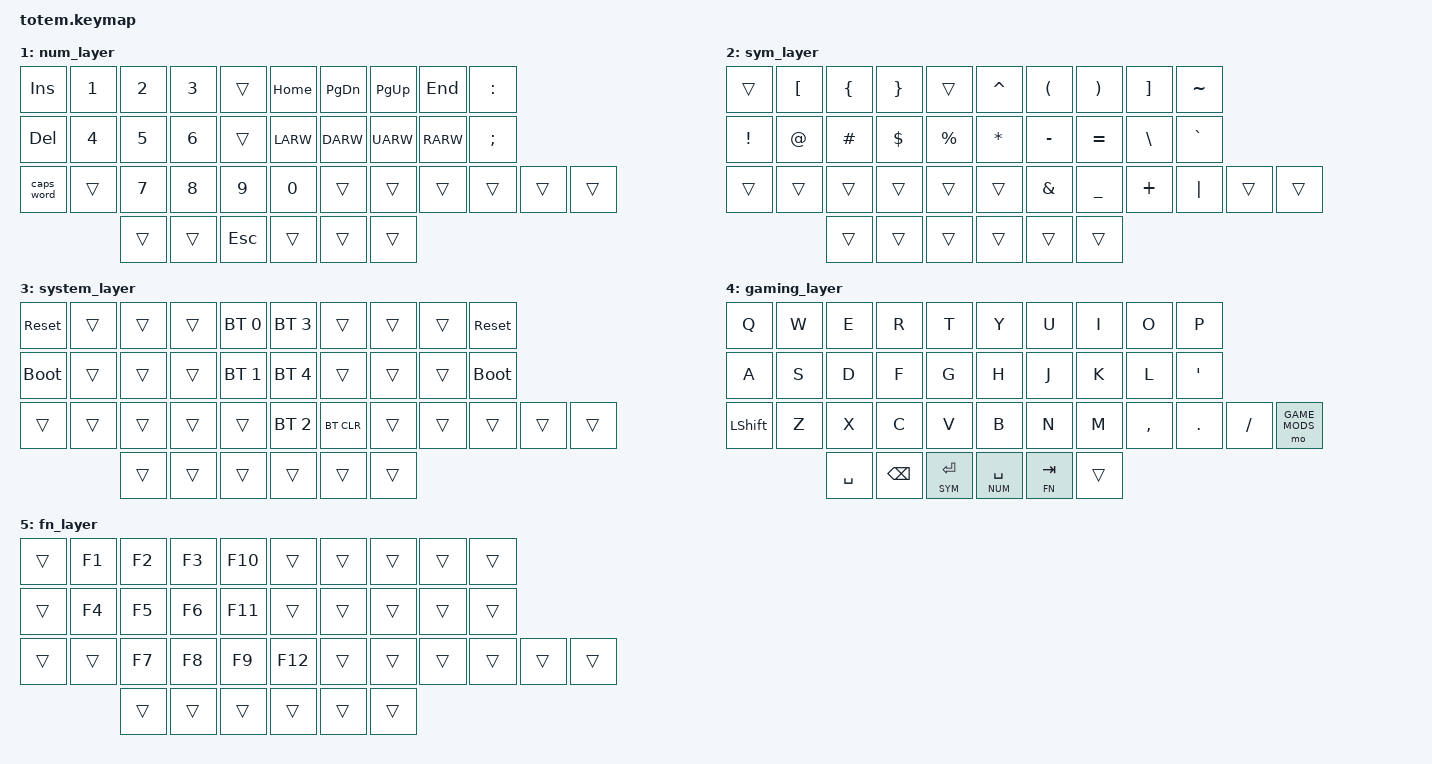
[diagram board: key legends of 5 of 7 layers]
//
//                                                        ▀▀▀▀▀     ▀▀▀▀▀          ▀▀█▀▀
//                                                        ▄▀▀▀▄  ▄  ▄▀▀▀▄  ▄  ▄▀▀▀▄  █  ▄▀▀▀▄
//                                                        █   █  █  █   █  █  █   █  █  █   █
//                                                         ▀▀▀   █   ▀▀▀   █   ▀▀▀   ▀   ▀▀▀
//                                                               █      ▄▄▄█▄▄▄    █   █  
//                                                               ▀      █  █  █     █▄█
//                                                             ▀▀▀▀▀    █  █  █      ▀
//                                                                      ▀  ▀  ▀
//
// Migrated from Crab Broom (34-key) to Totem (38-key) layout
//
// ▄▄▄▄▄▄▄▄▄▄▄▄▄▄▄▄▄▄▄▄▄▄▄▄▄▄▄▄▄▄▄▄▄▄▄▄▄▄▄▄▄▄▄▄▄▄▄▄▄▄▄▄▄▄▄▄▄▄▄▄▄▄▄▄▄▄▄▄▄▄▄▄▄▄▄▄▄▄▄▄▄▄▄▄▄▄▄▄▄▄▄▄▄▄▄▄▄▄▄▄▄▄▄▄▄▄▄▄▄▄▄▄▄▄▄▄▄▄▄▄▄▄▄▄▄▄▄▄▄▄▄▄▄▄▄▄▄▄▄▄▄▄▄▄▄▄▄▄▄

// Key position layout (Totem 38-key):
//             ┏━━━━━━━━━━━┳━━━━━━━━━━━┳━━━━━━━━━━━┳━━━━━━━━━━━┳━━━━━━━━━━━┓   ┏━━━━━━━━━━━┳━━━━━━━━━━━┳━━━━━━━━━━━┳━━━━━━━━━━━┳━━━━━━━━━━━┓
//             ┃     0     ┃     1     ┃     2     ┃     3     ┃     4     ┃   ┃     5     ┃     6     ┃     7     ┃     8     ┃     9     ┃
//             ┣━━━━━━━━━━━╋━━━━━━━━━━━╋━━━━━━━━━━━╋━━━━━━━━━━━╋━━━━━━━━━━━┫   ┣━━━━━━━━━━━╋━━━━━━━━━━━╋━━━━━━━━━━━╋━━━━━━━━━━━╋━━━━━━━━━━━┫
//             ┃    10     ┃    11     ┃    12     ┃    13     ┃    14     ┃   ┃    15     ┃    16     ┃    17     ┃    18     ┃    19     ┃
// ┏━━━━━━━━━━━╋━━━━━━━━━━━╋━━━━━━━━━━━╋━━━━━━━━━━━╋━━━━━━━━━━━╋━━━━━━━━━━━┫   ┣━━━━━━━━━━━╋━━━━━━━━━━━╋━━━━━━━━━━━╋━━━━━━━━━━━╋━━━━━━━━━━━╋━━━━━━━━━━━┓
// ┃    20     ┃    21     ┃    22     ┃    23     ┃    24     ┃    25     ┃   ┃    26     ┃    27     ┃    28     ┃    29     ┃    30     ┃    31     ┃
// ┗━━━━━━━━━━━┻━━━━━━━━━━━┻━━━━━━━━━━━╋━━━━━━━━━━━╋━━━━━━━━━━━╋━━━━━━━━━━━┫   ┣━━━━━━━━━━━╋━━━━━━━━━━━╋━━━━━━━━━━━╋━━━━━━━━━━━┻━━━━━━━━━━━┻━━━━━━━━━━━┛
//                                     ┃    32     ┃    33     ┃    34     ┃   ┃    35     ┃    36     ┃    37     ┃
//                                     ┗━━━━━━━━━━━┻━━━━━━━━━━━┻━━━━━━━━━━━┛   ┗━━━━━━━━━━━┻━━━━━━━━━━━┻━━━━━━━━━━━┛
       

#include <behaviors.dtsi>
#include <dt-bindings/zmk/keys.h>
#include <dt-bindings/zmk/bt.h>
#include <dt-bindings/zmk/outputs.h>

// Layer definitions
#define BASE      0  // Main typing layer with QWERTY + home row mods
#define NUM       1  // Numbers, navigation, and function keys  
#define SYM       2  // Symbols and special characters
#define SYS       3  // System controls (bluetooth, reset, etc.)
#define GAME      4  // Gaming layer without home row mods
#define FN        5  // Function keys layer (F1-F12)
#define GAME_MODS 6  // Gaming modifiers layer (home row mods for gaming)

// Home row mods macros
// Left hand: Shift/Alt/Ctrl/Gui on A/S/D/F
// Right hand: Gui/Ctrl/Alt/Shift on J/K/L/'
#define HRML(k1,k2,k3,k4) &ht LSHFT k1  &ht LALT k2  &ht LCTRL k3  &ht LGUI k4
#define HRMR(k1,k2,k3,k4) &ht RGUI k1  &ht RCTRL k2  &ht RALT k3  &ht RSHFT k4

&mt {
  quick-tap-ms = <150>;
  global-quick-tap;
  flavor = "tap-preferred";
  tapping-term-ms = <220>;
  require-prior-idle-ms = <100>;
};

/ {
    behaviors {
        ht: hold_tap {
            compatible = "zmk,behavior-hold-tap";
            #binding-cells = <2>;
            flavor = "tap-preferred";
            tapping-term-ms = <220>;
            quick-tap-ms = <150>;
            require-prior-idle-ms = <100>;
            bindings = <&kp>, <&kp>;
        };

        // Enables holding the first mod-tap key
        // by performing a tap-release-hold sequence.
        qt: quick_tap {
            compatible = "zmk,behavior-hold-tap";
            #binding-cells = <2>;
            flavor = "hold-preferred";
            tapping-term-ms = <200>;
            quick-tap-ms = <200>;
            bindings = <&kp>, <&kp>;
        };
    };

    macros {
        // sometimes my device thinks a modifier is being held down
        // pressing all modifiers fixes it.
        unstick: unstick {
            compatible = "zmk,behavior-macro";
            #binding-cells = <0>;
            bindings = <&kp LSHIFT &kp RSHIFT &kp LCTRL &kp RCTRL &kp LALT &kp RALT &kp LGUI &kp RGUI>;
        };
    };

     combos {
            compatible = "zmk,combos";
            // Toggle gaming layer by pressing ALL 6 thumb keys simultaneously
            // This prevents accidental gaming mode activation during normal typing
            combo_gaming {
                timeout-ms = <200>;
                key-positions = <32 33 34 35 36 37>;  // All thumb keys: LALT BSPC SYM+ENTER NUM+SPACE FN+TAB RALT
                bindings = <&tog GAME>;
            };
    };

    conditional_layers {
        compatible = "zmk,conditional-layers";
        // Activate SYS layer when both NUM and SYM layers are held
        // Provides access to system functions like bluetooth and reset
        tri_layer {
            if-layers = <NUM SYM>;
            then-layer = <SYS>;
        };
    };

        keymap {
                compatible = "zmk,keymap";
// ▄▄▄▄▄▄▄▄▄▄▄▄▄▄▄▄▄▄▄▄▄▄▄▄▄▄▄▄▄▄▄▄▄▄▄▄▄▄▄▄▄▄▄▄▄▄▄▄▄▄▄▄▄▄▄▄▄▄▄▄▄▄▄▄▄▄▄▄▄▄▄▄▄▄▄▄▄▄▄▄▄▄▄▄▄▄▄▄▄▄▄▄▄▄▄▄▄▄▄▄▄▄▄▄▄▄▄▄▄▄▄▄▄▄▄▄▄▄▄▄▄▄▄▄▄▄▄▄▄▄▄▄▄▄▄▄▄▄▄▄▄▄▄▄▄▄▄▄▄

                base_layer {
// ┏━━━━━━━━━━━━━━━━━━━━━━━━━━━━━━━━━━━━━━━┓
// Base Layer
// ┗━━━━━━━━━━━━━━━━━━━━━━━━━━━━━━━━━━━━━━━┛
// Main QWERTY layer with home row mods for efficient typing
// Home row mods: A/S/D/F = Shift/Alt/Ctrl/Gui (left hand)
//                J/K/L/' = Gui/Ctrl/Alt/Shift (right hand)
//             ┏━━━━━━━━━━━┳━━━━━━━━━━━┳━━━━━━━━━━━┳━━━━━━━━━━━┳━━━━━━━━━━━┓   ┏━━━━━━━━━━━┳━━━━━━━━━━━┳━━━━━━━━━━━┳━━━━━━━━━━━┳━━━━━━━━━━━┓
//             ┃     Q     ┃     W     ┃     E     ┃     R     ┃     T     ┃   ┃     Y     ┃     U     ┃     I     ┃     O     ┃     P     ┃
//             ┣━━━━━━━━━━━╋━━━━━━━━━━━╋━━━━━━━━━━━╋━━━━━━━━━━━╋━━━━━━━━━━━┫   ┣━━━━━━━━━━━╋━━━━━━━━━━━╋━━━━━━━━━━━╋━━━━━━━━━━━╋━━━━━━━━━━━┫
//             ┃  A/SHFT   ┃   S/ALT   ┃  D/CTRL   ┃   F/GUI   ┃     G     ┃   ┃     H     ┃   J/GUI   ┃  K/CTRL   ┃   L/ALT   ┃ '/SHFT    ┃
// ┏━━━━━━━━━━━╋━━━━━━━━━━━╋━━━━━━━━━━━╋━━━━━━━━━━━╋━━━━━━━━━━━╋━━━━━━━━━━━┫   ┣━━━━━━━━━━━╋━━━━━━━━━━━╋━━━━━━━━━━━╋━━━━━━━━━━━╋━━━━━━━━━━━╋━━━━━━━━━━━┓
// ┃   SHIFT   ┃     Z     ┃     X     ┃     C     ┃     V     ┃     B     ┃   ┃     N     ┃     M     ┃     ,     ┃     .     ┃     /     ┃   SHIFT   ┃
// ┗━━━━━━━━━━━┻━━━━━━━━━━━┻━━━━━━━━━━━╋━━━━━━━━━━━╋━━━━━━━━━━━╋━━━━━━━━━━━┫   ┣━━━━━━━━━━━╋━━━━━━━━━━━╋━━━━━━━━━━━╋━━━━━━━━━━━┻━━━━━━━━━━━┻━━━━━━━━━━━┛
//                                     ┃   LALT    ┃   BSPC    ┃SYM+ENTER  ┃   ┃NUM+SPACE  ┃  FN+TAB   ┃   RALT    ┃
//                                     ┗━━━━━━━━━━━┻━━━━━━━━━━━┻━━━━━━━━━━━┛   ┗━━━━━━━━━━━┻━━━━━━━━━━━┻━━━━━━━━━━━┛
 bindings = <
// ╷           ╷           ╷           ╷           ╷           ╷           ╷   ╷           ╷           ╷           ╷           ╷           ╷           ╷
//   0           1           2           3           4               5           6           7           8           9
    &kp Q       &kp W       &kp E       &kp R       &kp T           &kp Y       &kp U       &kp I       &kp O       &kp P
//   10          11          12          13          14              15          16          17          18          19
  HRML(A,         S,          D,          F)        &kp G           &kp H     HRMR(J,         K,          L,        SQT) 
//   20          21          22          23          24          25              26          27          28          29          30          31
&kp LSHFT     &kp Z       &kp X       &kp C       &kp V       &kp B           &kp N       &kp M       &kp COMMA   &kp DOT     &kp FSLH    &kp RSHFT
//                          32          33          34              35          36          37
                            &kp LALT    &kp BSPC    &lt SYM ENTER   &lt NUM SPACE  &lt FN TAB   &kp RALT
                        >;
                };

// ▄▄▄▄▄▄▄▄▄▄▄▄▄▄▄▄▄▄▄▄▄▄▄▄▄▄▄▄▄▄▄▄▄▄▄▄▄▄▄▄▄▄▄▄▄▄▄▄▄▄▄▄▄▄▄▄▄▄▄▄▄▄▄▄▄▄▄▄▄▄▄▄▄▄▄▄▄▄▄▄▄▄▄▄▄▄▄▄▄▄▄▄▄▄▄▄▄▄▄▄▄▄▄▄▄▄▄▄▄▄▄▄▄▄▄▄▄▄▄▄▄▄▄▄▄▄▄▄▄▄▄▄▄▄▄▄▄▄▄▄▄▄▄▄▄▄▄▄▄


                num_layer {
// ┏━━━━━━━━━━━━━━━━━━━━━━━━━━━━━━━━━━━━━━━┓
// Numbers Layer
// ┗━━━━━━━━━━━━━━━━━━━━━━━━━━━━━━━━━━━━━━━┛
//             ┏━━━━━━━━━━━┳━━━━━━━━━━━┳━━━━━━━━━━━┳━━━━━━━━━━━┳━━━━━━━━━━━┓   ┏━━━━━━━━━━━┳━━━━━━━━━━━┳━━━━━━━━━━━┳━━━━━━━━━━━┳━━━━━━━━━━━┓
//             ┃   INSERT  ┃     1     ┃     2     ┃     3     ┃           ┃   ┃   HOME    ┃  PAGE DN  ┃  PAGE UP  ┃    END    ┃     :     ┃
//             ┣━━━━━━━━━━━╋━━━━━━━━━━━╋━━━━━━━━━━━╋━━━━━━━━━━━╋━━━━━━━━━━━┫   ┣━━━━━━━━━━━╋━━━━━━━━━━━╋━━━━━━━━━━━╋━━━━━━━━━━━╋━━━━━━━━━━━┫
//             ┃   DELETE  ┃     4     ┃     5     ┃     6     ┃           ┃   ┃   LEFT    ┃   DOWN    ┃    UP     ┃   RIGHT   ┃     ;     ┃
// ┏━━━━━━━━━━━╋━━━━━━━━━━━╋━━━━━━━━━━━╋━━━━━━━━━━━╋━━━━━━━━━━━╋━━━━━━━━━━━┫   ┣━━━━━━━━━━━╋━━━━━━━━━━━╋━━━━━━━━━━━╋━━━━━━━━━━━╋━━━━━━━━━━━╋━━━━━━━━━━━┓
// ┃  CAPS WRD ┃           ┃     7     ┃     8     ┃     9     ┃     0     ┃   ┃           ┃           ┃           ┃           ┃           ┃           ┃
// ┗━━━━━━━━━━━┻━━━━━━━━━━━┻━━━━━━━━━━━╋━━━━━━━━━━━╋━━━━━━━━━━━╋━━━━━━━━━━━┫   ┣━━━━━━━━━━━╋━━━━━━━━━━━╋━━━━━━━━━━━╋━━━━━━━━━━━┻━━━━━━━━━━━┻━━━━━━━━━━━┛
//                                     ┃  ▽ LALT   ┃  ▽ BSPC   ┃    ESC    ┃   ┃  ▽ HELD   ┃ ▽ FN+TAB  ┃  ▽ RALT   ┃
//                                     ┗━━━━━━━━━━━┻━━━━━━━━━━━┻━━━━━━━━━━━┛   ┗━━━━━━━━━━━┻━━━━━━━━━━━┻━━━━━━━━━━━┛
 bindings = <
// ╷           ╷           ╷           ╷           ╷           ╷           ╷   ╷           ╷           ╷           ╷           ╷           ╷           ╷
//   0           1           2           3           4               5           6           7           8           9
    &kp INS     &kp N1      &kp N2      &kp N3      &trans          &kp HOME    &kp PG_DN   &kp PG_UP   &kp END     &kp COLON
//   10          11          12          13          14              15          16          17          18          19
    &kp DEL     &kp N4      &kp N5      &kp N6      &trans          &kp LARW    &kp DARW    &kp UARW    &kp RARW    &kp SEMI
//   20          21          22          23          24          25              26          27          28          29          30          31
  &caps_word    &trans      &kp N7      &kp N8      &kp N9      &kp N0          &trans      &trans      &trans      &trans      &trans      &trans      
//                          32          33          34              35          36          37
                            &trans      &trans      &kp ESC         &trans      &trans      &trans      
                        >;
                };

// ▄▄▄▄▄▄▄▄▄▄▄▄▄▄▄▄▄▄▄▄▄▄▄▄▄▄▄▄▄▄▄▄▄▄▄▄▄▄▄▄▄▄▄▄▄▄▄▄▄▄▄▄▄▄▄▄▄▄▄▄▄▄▄▄▄▄▄▄▄▄▄▄▄▄▄▄▄▄▄▄▄▄▄▄▄▄▄▄▄▄▄▄▄▄▄▄▄▄▄▄▄▄▄▄▄▄▄▄▄▄▄▄▄▄▄▄▄▄▄▄▄▄▄▄▄▄▄▄▄▄▄▄▄▄▄▄▄▄▄▄▄▄▄▄▄▄▄▄▄


                sym_layer {
// ┏━━━━━━━━━━━━━━━━━━━━━━━━━━━━━━━━━━━━━━━┓
// Symbols Layer
// ┗━━━━━━━━━━━━━━━━━━━━━━━━━━━━━━━━━━━━━━━┛
//             ┏━━━━━━━━━━━┳━━━━━━━━━━━┳━━━━━━━━━━━┳━━━━━━━━━━━┳━━━━━━━━━━━┓   ┏━━━━━━━━━━━┳━━━━━━━━━━━┳━━━━━━━━━━━┳━━━━━━━━━━━┳━━━━━━━━━━━┓
//             ┃           ┃     [     ┃     {     ┃     }     ┃           ┃   ┃     ^     ┃     (     ┃     )     ┃     ]     ┃     ~     ┃
//             ┣━━━━━━━━━━━╋━━━━━━━━━━━╋━━━━━━━━━━━╋━━━━━━━━━━━╋━━━━━━━━━━━┫   ┣━━━━━━━━━━━╋━━━━━━━━━━━╋━━━━━━━━━━━╋━━━━━━━━━━━╋━━━━━━━━━━━┫
//             ┃     !     ┃     @     ┃     #     ┃     $     ┃     %     ┃   ┃     *     ┃     -     ┃     =     ┃     \     ┃     `     ┃
// ┏━━━━━━━━━━━╋━━━━━━━━━━━╋━━━━━━━━━━━╋━━━━━━━━━━━╋━━━━━━━━━━━╋━━━━━━━━━━━┫   ┣━━━━━━━━━━━╋━━━━━━━━━━━╋━━━━━━━━━━━╋━━━━━━━━━━━╋━━━━━━━━━━━╋━━━━━━━━━━━┓
// ┃           ┃           ┃           ┃           ┃           ┃           ┃   ┃     &     ┃     _     ┃     +     ┃     |     ┃           ┃           ┃
// ┗━━━━━━━━━━━┻━━━━━━━━━━━┻━━━━━━━━━━━╋━━━━━━━━━━━╋━━━━━━━━━━━╋━━━━━━━━━━━┫   ┣━━━━━━━━━━━╋━━━━━━━━━━━╋━━━━━━━━━━━╋━━━━━━━━━━━┻━━━━━━━━━━━┻━━━━━━━━━━━┛
//                                     ┃           ┃           ┃           ┃   ┃           ┃           ┃           ┃
//                                     ┗━━━━━━━━━━━┻━━━━━━━━━━━┻━━━━━━━━━━━┛   ┗━━━━━━━━━━━┻━━━━━━━━━━━┻━━━━━━━━━━━┛
 bindings = <
// ╷           ╷           ╷           ╷           ╷           ╷           ╷   ╷           ╷           ╷           ╷           ╷           ╷           ╷
//   0           1           2           3           4               5           6           7           8           9
    &trans      &kp LBKT    &kp LBRC    &kp RBRC    &trans          &kp CARET   &kp LPAR    &kp RPAR    &kp RBKT    &kp TILDE
//   10          11          12          13          14              15          16          17          18          19
    &kp EXCL    &kp AT      &kp HASH    &kp DLLR    &kp PRCNT       &kp ASTRK   &kp MINUS   &kp EQUAL   &kp BSLH    &kp GRAVE
//   20          21          22          23          24          25              26          27          28          29          30          31
    &trans      &trans      &trans      &trans      &trans      &trans          &kp AMPS    &kp UNDER   &kp PLUS    &kp PIPE    &trans      &trans      
//                          32          33          34              35          36          37
                            &trans      &trans      &trans          &trans      &trans      &trans      
                        >;
                };

// ▄▄▄▄▄▄▄▄▄▄▄▄▄▄▄▄▄▄▄▄▄▄▄▄▄▄▄▄▄▄▄▄▄▄▄▄▄▄▄▄▄▄▄▄▄▄▄▄▄▄▄▄▄▄▄▄▄▄▄▄▄▄▄▄▄▄▄▄▄▄▄▄▄▄▄▄▄▄▄▄▄▄▄▄▄▄▄▄▄▄▄▄▄▄▄▄▄▄▄▄▄▄▄▄▄▄▄▄▄▄▄▄▄▄▄▄▄▄▄▄▄▄▄▄▄▄▄▄▄▄▄▄▄▄▄▄▄▄▄▄▄▄▄▄▄▄▄▄▄


                system_layer {
// ┏━━━━━━━━━━━━━━━━━━━━━━━━━━━━━━━━━━━━━━━┓
// System Layer
// ┗━━━━━━━━━━━━━━━━━━━━━━━━━━━━━━━━━━━━━━━┛
//             ┏━━━━━━━━━━━┳━━━━━━━━━━━┳━━━━━━━━━━━┳━━━━━━━━━━━┳━━━━━━━━━━━┓   ┏━━━━━━━━━━━┳━━━━━━━━━━━┳━━━━━━━━━━━┳━━━━━━━━━━━┳━━━━━━━━━━━┓
//             ┃   RESET   ┃           ┃           ┃           ┃PROFILE 0  ┃   ┃PROFILE 3  ┃           ┃           ┃           ┃   RESET   ┃
//             ┣━━━━━━━━━━━╋━━━━━━━━━━━╋━━━━━━━━━━━╋━━━━━━━━━━━╋━━━━━━━━━━━┫   ┣━━━━━━━━━━━╋━━━━━━━━━━━╋━━━━━━━━━━━╋━━━━━━━━━━━╋━━━━━━━━━━━┫
//             ┃BOOTLOADER ┃           ┃           ┃           ┃PROFILE 1  ┃   ┃PROFILE 4  ┃           ┃           ┃           ┃BOOTLOADER ┃
// ┏━━━━━━━━━━━╋━━━━━━━━━━━╋━━━━━━━━━━━╋━━━━━━━━━━━╋━━━━━━━━━━━╋━━━━━━━━━━━┫   ┣━━━━━━━━━━━╋━━━━━━━━━━━╋━━━━━━━━━━━╋━━━━━━━━━━━╋━━━━━━━━━━━╋━━━━━━━━━━━┓
// ┃           ┃           ┃           ┃           ┃           ┃PROFILE 2  ┃   ┃ CLEAR BT  ┃           ┃           ┃           ┃           ┃           ┃
// ┗━━━━━━━━━━━┻━━━━━━━━━━━┻━━━━━━━━━━━╋━━━━━━━━━━━╋━━━━━━━━━━━╋━━━━━━━━━━━┫   ┣━━━━━━━━━━━╋━━━━━━━━━━━╋━━━━━━━━━━━╋━━━━━━━━━━━┻━━━━━━━━━━━┻━━━━━━━━━━━┛
//                                     ┃           ┃           ┃           ┃   ┃           ┃           ┃           ┃
//                                     ┗━━━━━━━━━━━┻━━━━━━━━━━━┻━━━━━━━━━━━┛   ┗━━━━━━━━━━━┻━━━━━━━━━━━┻━━━━━━━━━━━┛
 bindings = <
// ╷           ╷           ╷           ╷           ╷           ╷           ╷   ╷           ╷           ╷           ╷           ╷           ╷           ╷
//   0           1           2           3           4               5           6           7           8           9
   &sys_reset   &trans      &trans      &trans     &bt BT_SEL 0    &bt BT_SEL 3  &trans      &trans      &trans     &sys_reset
//   10          11          12          13          14              15          16          17          18          19
   &bootloader  &trans      &trans      &trans     &bt BT_SEL 1    &bt BT_SEL 4  &trans      &trans      &trans     &bootloader
//   20          21          22          23          24          25              26          27          28          29          30          31
    &trans     &trans       &trans      &trans      &trans     &bt BT_SEL 2    &bt BT_CLR    &trans      &trans      &trans     &trans      &trans         
//                          32          33          34              35          36          37
                            &trans      &trans     &trans          &trans        &trans      &trans      
                        >;
                };

// ▄▄▄▄▄▄▄▄▄▄▄▄▄▄▄▄▄▄▄▄▄▄▄▄▄▄▄▄▄▄▄▄▄▄▄▄▄▄▄▄▄▄▄▄▄▄▄▄▄▄▄▄▄▄▄▄▄▄▄▄▄▄▄▄▄▄▄▄▄▄▄▄▄▄▄▄▄▄▄▄▄▄▄▄▄▄▄▄▄▄▄▄▄▄▄▄▄▄▄▄▄▄▄▄▄▄▄▄▄▄▄▄▄▄▄▄▄▄▄▄▄▄▄▄▄▄▄▄▄▄▄▄▄▄▄▄▄▄▄▄▄▄▄▄▄▄▄▄▄


                gaming_layer {
// ┏━━━━━━━━━━━━━━━━━━━━━━━━━━━━━━━━━━━━━━━┓
// Gaming Layer
// ┗━━━━━━━━━━━━━━━━━━━━━━━━━━━━━━━━━━━━━━━┛
// Gaming layer with identical letter layout to base layer
// - All letter keys in same positions as base layer for consistency
// - No home row mods to prevent accidental activation during gameplay
// - Positions 20/31 access GAME_MODS layer for home row modifiers when needed
// - Direct Enter for chat, NUM layer for numbers, FN layer for function keys
// - ALT keys pass through from base layer (pos 32/37) on thumbs for quick modifiers
//             ┏━━━━━━━━━━━┳━━━━━━━━━━━┳━━━━━━━━━━━┳━━━━━━━━━━━┳━━━━━━━━━━━┓   ┏━━━━━━━━━━━┳━━━━━━━━━━━┳━━━━━━━━━━━┳━━━━━━━━━━━┳━━━━━━━━━━━┓
//             ┃     Q     ┃     W     ┃     E     ┃     R     ┃     T     ┃   ┃     Y     ┃     U     ┃     I     ┃     O     ┃     P     ┃
//             ┣━━━━━━━━━━━╋━━━━━━━━━━━╋━━━━━━━━━━━╋━━━━━━━━━━━╋━━━━━━━━━━━┫   ┣━━━━━━━━━━━╋━━━━━━━━━━━╋━━━━━━━━━━━╋━━━━━━━━━━━╋━━━━━━━━━━━┫
//             ┃     A     ┃     S     ┃     D     ┃     F     ┃     G     ┃   ┃     H     ┃     J     ┃     K     ┃     L     ┃     '     ┃
// ┏━━━━━━━━━━━╋━━━━━━━━━━━╋━━━━━━━━━━━╋━━━━━━━━━━━╋━━━━━━━━━━━╋━━━━━━━━━━━┫   ┣━━━━━━━━━━━╋━━━━━━━━━━━╋━━━━━━━━━━━╋━━━━━━━━━━━╋━━━━━━━━━━━╋━━━━━━━━━━━┓
// ┃  LSHIFT   ┃     Z     ┃     X     ┃     C     ┃     V     ┃     B     ┃   ┃     N     ┃     M     ┃     ,     ┃     .     ┃     /     ┃GAME_MODS  ┃
// ┗━━━━━━━━━━━┻━━━━━━━━━━━┻━━━━━━━━━━━╋━━━━━━━━━━━╋━━━━━━━━━━━╋━━━━━━━━━━━┫   ┣━━━━━━━━━━━╋━━━━━━━━━━━╋━━━━━━━━━━━╋━━━━━━━━━━━┻━━━━━━━━━━━┻━━━━━━━━━━━┛
//                                     ┃   SPACE   ┃   BSPC    ┃SYM+ENTER  ┃   ┃NUM+SPACE  ┃  FN+TAB   ┃  ▽ RALT   ┃
//                                     ┗━━━━━━━━━━━┻━━━━━━━━━━━┻━━━━━━━━━━━┛   ┗━━━━━━━━━━━┻━━━━━━━━━━━┻━━━━━━━━━━━┛
 bindings = <
// ╷           ╷           ╷           ╷           ╷           ╷           ╷   ╷           ╷           ╷           ╷           ╷           ╷           ╷
//   0           1           2           3           4               5           6           7           8           9
    &kp Q       &kp W       &kp E       &kp R       &kp T           &kp Y       &kp U       &kp I       &kp O       &kp P
//   10          11          12          13          14              15          16          17          18          19
    &kp A       &kp S       &kp D       &kp F       &kp G           &kp H       &kp J       &kp K       &kp L       &kp SQT
//   20          21          22          23          24          25              26          27          28          29          30          31
&kp LSHFT     &kp Z       &kp X       &kp C       &kp V       &kp B           &kp N       &kp M       &kp COMMA   &kp DOT     &kp FSLH    &mo GAME_MODS        
//                          32          33          34              35          36          37
                            &kp SPACE   &kp BSPC    &lt SYM ENTER   &lt NUM SPACE  &lt FN TAB   &trans    
                        >;
                };

// ▄▄▄▄▄▄▄▄▄▄▄▄▄▄▄▄▄▄▄▄▄▄▄▄▄▄▄▄▄▄▄▄▄▄▄▄▄▄▄▄▄▄▄▄▄▄▄▄▄▄▄▄▄▄▄▄▄▄▄▄▄▄▄▄▄▄▄▄▄▄▄▄▄▄▄▄▄▄▄▄▄▄▄▄▄▄▄▄▄▄▄▄▄▄▄▄▄▄▄▄▄▄▄▄▄▄▄▄▄▄▄▄▄▄▄▄▄▄▄▄▄▄▄▄▄▄▄▄▄▄▄▄▄▄▄▄▄▄▄▄▄▄▄▄▄▄▄▄▄

                fn_layer {
// ┏━━━━━━━━━━━━━━━━━━━━━━━━━━━━━━━━━━━━━━━┓
// Function Keys Layer
// ┗━━━━━━━━━━━━━━━━━━━━━━━━━━━━━━━━━━━━━━━┛
// Function keys layer - accessed via TAB key hold (position 36)
// F1-F9 arranged in same positions as NUM layer numbers 1-9
// F10-F12 in the rightmost column of LEFT half for easy access
//             ┏━━━━━━━━━━━┳━━━━━━━━━━━┳━━━━━━━━━━━┳━━━━━━━━━━━┳━━━━━━━━━━━┓   ┏━━━━━━━━━━━┳━━━━━━━━━━━┳━━━━━━━━━━━┳━━━━━━━━━━━┳━━━━━━━━━━━┓
//             ┃           ┃    F1     ┃    F2     ┃    F3     ┃    F10    ┃   ┃           ┃           ┃           ┃           ┃           ┃
//             ┣━━━━━━━━━━━╋━━━━━━━━━━━╋━━━━━━━━━━━╋━━━━━━━━━━━╋━━━━━━━━━━━┫   ┣━━━━━━━━━━━╋━━━━━━━━━━━╋━━━━━━━━━━━╋━━━━━━━━━━━╋━━━━━━━━━━━┫
//             ┃           ┃    F4     ┃    F5     ┃    F6     ┃    F11    ┃   ┃           ┃           ┃           ┃           ┃           ┃
// ┏━━━━━━━━━━━╋━━━━━━━━━━━╋━━━━━━━━━━━╋━━━━━━━━━━━╋━━━━━━━━━━━╋━━━━━━━━━━━┫   ┣━━━━━━━━━━━╋━━━━━━━━━━━╋━━━━━━━━━━━╋━━━━━━━━━━━╋━━━━━━━━━━━╋━━━━━━━━━━━┓
// ┃           ┃           ┃    F7     ┃    F8     ┃    F9     ┃    F12    ┃   ┃           ┃           ┃           ┃           ┃           ┃           ┃
// ┗━━━━━━━━━━━┻━━━━━━━━━━━┻━━━━━━━━━━━╋━━━━━━━━━━━╋━━━━━━━━━━━╋━━━━━━━━━━━┫   ┣━━━━━━━━━━━╋━━━━━━━━━━━╋━━━━━━━━━━━╋━━━━━━━━━━━┻━━━━━━━━━━━┻━━━━━━━━━━━┛
//                                     ┃           ┃           ┃           ┃   ┃           ┃           ┃           ┃
//                                     ┗━━━━━━━━━━━┻━━━━━━━━━━━┻━━━━━━━━━━━┛   ┗━━━━━━━━━━━┻━━━━━━━━━━━┻━━━━━━━━━━━┛
 bindings = <
// ╷           ╷           ╷           ╷           ╷           ╷           ╷   ╷           ╷           ╷           ╷           ╷           ╷           ╷
//   0           1           2           3           4               5           6           7           8           9
    &trans      &kp F1      &kp F2      &kp F3      &kp F10         &trans      &trans      &trans      &trans      &trans
//   10          11          12          13          14              15          16          17          18          19
    &trans      &kp F4      &kp F5      &kp F6      &kp F11         &trans      &trans      &trans      &trans      &trans
//   20          21          22          23          24          25              26          27          28          29          30          31
    &trans      &trans      &kp F7      &kp F8      &kp F9      &kp F12         &trans      &trans      &trans      &trans      &trans      &trans      
//                          32          33          34              35          36          37
                            &trans      &trans      &trans          &trans      &trans      &trans      
                        >;
                };

// ▄▄▄▄▄▄▄▄▄▄▄▄▄▄▄▄▄▄▄▄▄▄▄▄▄▄▄▄▄▄▄▄▄▄▄▄▄▄▄▄▄▄▄▄▄▄▄▄▄▄▄▄▄▄▄▄▄▄▄▄▄▄▄▄▄▄▄▄▄▄▄▄▄▄▄▄▄▄▄▄▄▄▄▄▄▄▄▄▄▄▄▄▄▄▄▄▄▄▄▄▄▄▄▄▄▄▄▄▄▄▄▄▄▄▄▄▄▄▄▄▄▄▄▄▄▄▄▄▄▄▄▄▄▄▄▄▄▄▄▄▄▄▄▄▄▄▄▄▄

                game_mods_layer {
// ┏━━━━━━━━━━━━━━━━━━━━━━━━━━━━━━━━━━━━━━━┓
// Game Modifiers Layer
// ┗━━━━━━━━━━━━━━━━━━━━━━━━━━━━━━━━━━━━━━━┛
// Gaming modifiers layer - accessed via SHIFT keys on gaming layer (positions 20/31)
// Provides home row modifiers when needed during gaming
// All positions transparent except home row which has identical mods to base layer
//             ┏━━━━━━━━━━━┳━━━━━━━━━━━┳━━━━━━━━━━━┳━━━━━━━━━━━┳━━━━━━━━━━━┓   ┏━━━━━━━━━━━┳━━━━━━━━━━━┳━━━━━━━━━━━┳━━━━━━━━━━━┳━━━━━━━━━━━┓
//             ┃           ┃           ┃           ┃           ┃           ┃   ┃           ┃           ┃           ┃           ┃           ┃
//             ┣━━━━━━━━━━━╋━━━━━━━━━━━╋━━━━━━━━━━━╋━━━━━━━━━━━╋━━━━━━━━━━━┫   ┣━━━━━━━━━━━╋━━━━━━━━━━━╋━━━━━━━━━━━╋━━━━━━━━━━━╋━━━━━━━━━━━┫
//             ┃  A/SHFT   ┃   S/ALT   ┃  D/CTRL   ┃   F/GUI   ┃           ┃   ┃           ┃   J/GUI   ┃  K/CTRL   ┃   L/ALT   ┃ '/SHFT    ┃
// ┏━━━━━━━━━━━╋━━━━━━━━━━━╋━━━━━━━━━━━╋━━━━━━━━━━━╋━━━━━━━━━━━╋━━━━━━━━━━━┫   ┣━━━━━━━━━━━╋━━━━━━━━━━━╋━━━━━━━━━━━╋━━━━━━━━━━━╋━━━━━━━━━━━╋━━━━━━━━━━━┓
// ┃           ┃           ┃           ┃           ┃           ┃           ┃   ┃           ┃           ┃           ┃           ┃           ┃           ┃
// ┗━━━━━━━━━━━┻━━━━━━━━━━━┻━━━━━━━━━━━╋━━━━━━━━━━━╋━━━━━━━━━━━╋━━━━━━━━━━━┫   ┣━━━━━━━━━━━╋━━━━━━━━━━━╋━━━━━━━━━━━╋━━━━━━━━━━━┻━━━━━━━━━━━┻━━━━━━━━━━━┛
//                                     ┃           ┃           ┃           ┃   ┃           ┃           ┃           ┃
//                                     ┗━━━━━━━━━━━┻━━━━━━━━━━━┻━━━━━━━━━━━┛   ┗━━━━━━━━━━━┻━━━━━━━━━━━┻━━━━━━━━━━━┛
 bindings = <
// ╷           ╷           ╷           ╷           ╷           ╷           ╷   ╷           ╷           ╷           ╷           ╷           ╷           ╷
//   0           1           2           3           4               5           6           7           8           9
    &trans      &trans      &trans      &trans      &trans          &trans      &trans      &trans      &trans      &trans
//   10          11          12          13          14              15          16          17          18          19
  HRML(A,         S,          D,          F)        &trans          &trans    HRMR(J,         K,          L,        SQT) 
//   20          21          22          23          24          25              26          27          28          29          30          31
    &trans      &trans      &trans      &trans      &trans      &trans          &trans      &trans      &trans      &trans      &trans      &trans      
//                          32          33          34              35          36          37
                            &trans      &trans      &trans          &trans      &trans      &trans      
                        >;
                };
        };
};
